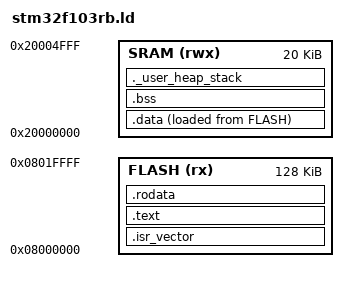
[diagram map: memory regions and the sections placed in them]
ENTRY(Reset_Handler)

/* Highest address of the user mode stack */
_estack = ORIGIN(SRAM) + LENGTH(SRAM); /* end of "RAM" Ram type memory */

_Min_Heap_Size = 0x200 ; /* required amount of heap */
_Min_Stack_Size = 0x400 ; /* required amount of stack */

MEMORY
{
	FLASH(rx) : ORIGIN = 0x08000000, LENGTH = 128K
	SRAM(rwx) : ORIGIN = 0x20000000, LENGTH = 20K
}

SECTIONS
{
	.isr_vector :
	{
		. = ALIGN(4);
		KEEP(*(.isr_vector)) /* Startup code */
		. = ALIGN(4);
	} >FLASH

	.text :
	{
		. = ALIGN(4);
		*(.text)
		*(.text*)
		. = ALIGN(4);
		_etext = .;
	} >FLASH

	.rodata :
	{
		. = ALIGN(4);
		*(.rodata)         /* .rodata sections (constants, strings, etc.) */
		*(.rodata*)        /* .rodata* sections (constants, strings, etc.) */
		. = ALIGN(4);
	} >FLASH
	
	/* Utiliser dans le startup pour initialiser les datas*/
	_sidata = LOADADDR(.data);

	.data :
	{
		. = ALIGN(4);
		_sdata = .;
		*(.data)
		*(.data*)
		. = ALIGN(4);
		_edata = .;
	} >SRAM AT> FLASH

	.bss :
	{
		. = ALIGN(4);
		_sbss = .;
		__bss_start__ = _sbss;
		*(.bss)
		*(.bss*)
		. = ALIGN(4);
		_ebss = .;
		__bss_end__ = _ebss;
	} >SRAM

	._user_heap_stack :
	{
		. = ALIGN(8);
		PROVIDE ( end = . );
		PROVIDE ( _end = . );
		. = . + _Min_Heap_Size;
		. = . + _Min_Stack_Size;
		. = ALIGN(8);
	} >SRAM

	/* Remove information from the compiler libraries */
	/DISCARD/ :
	{
		libc.a ( * )
		libm.a ( * )
		libgcc.a ( * )
	}
}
